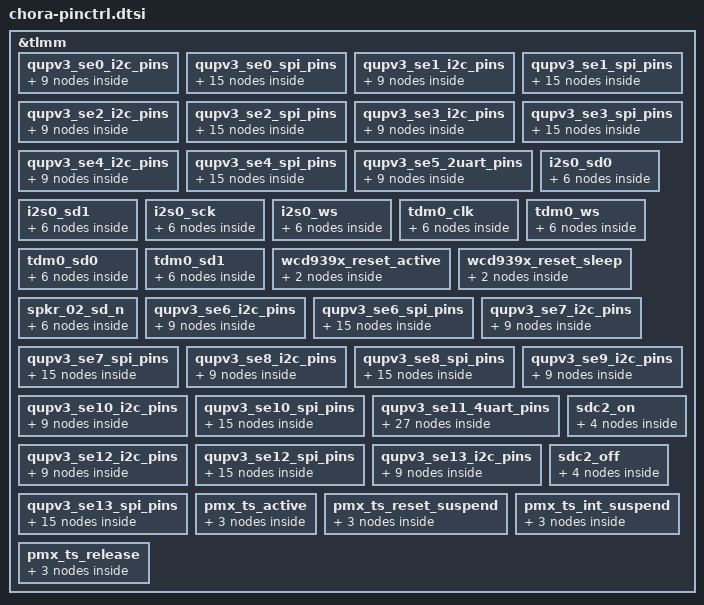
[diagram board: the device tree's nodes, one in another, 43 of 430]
// SPDX-License-Identifier: BSD-3-Clause
/*
 * Copyright (c) Qualcomm Technologies, Inc. and/or its subsidiaries.
 */

&tlmm {
	qupv3_se0_i2c_pins: qupv3_se0_i2c_pins {
		qupv3_se0_i2c_sda_active: qupv3_se0_i2c_sda_active {
			mux {
				pins = "gpio0";
				function = "qup0_se0_l0";
			};

			config {
				pins = "gpio0";
				drive-strength = <2>;
				bias-pull-up;
				qcom,i2c_pull;
			};
		};

		qupv3_se0_i2c_scl_active: qupv3_se0_i2c_scl_active {
			mux {
				pins = "gpio1";
				function = "qup0_se0_l1";
			};

			config {
				pins = "gpio1";
				drive-strength = <2>;
				bias-pull-up;
				qcom,i2c_pull;
			};
		};

		qupv3_se0_i2c_sleep: qupv3_se0_i2c_sleep {
			mux {
				pins = "gpio0", "gpio1";
				function = "gpio";
			};

			config {
				pins = "gpio0", "gpio1";
				drive-strength = <2>;
			};
		};
	};

	qupv3_se0_spi_pins: qupv3_se0_spi_pins {
		qupv3_se0_spi_miso_active: qupv3_se0_spi_miso_active {
			mux {
				pins = "gpio0";
				function = "qup0_se0_l0";
			};

			config {
				pins = "gpio0";
				drive-strength = <6>;
				bias-disable;
			};
		};

		qupv3_se0_spi_mosi_active: qupv3_se0_spi_mosi_active {
			mux {
				pins = "gpio1";
				function = "qup0_se0_l1";
			};

			config {
				pins = "gpio1";
				drive-strength = <6>;
				bias-disable;
			};
		};

		qupv3_se0_spi_clk_active: qupv3_se0_spi_clk_active {
			mux {
				pins = "gpio2";
				function = "qup0_se0_l2";
			};

			config {
				pins = "gpio2";
				drive-strength = <6>;
				bias-disable;
			};
		};

		qupv3_se0_spi_cs_active: qupv3_se0_spi_cs_active {
			mux {
				pins = "gpio3";
				function = "qup0_se0_l3";
			};

			config {
				pins = "gpio3";
				drive-strength = <6>;
				bias-disable;
			};
		};

		qupv3_se0_spi_sleep: qupv3_se0_spi_sleep {
			mux {
				pins = "gpio0", "gpio1",
					"gpio2", "gpio3";
				function = "gpio";
			};

			config {
				pins = "gpio0", "gpio1",
					"gpio2", "gpio3";
				drive-strength = <2>;
				bias-disable;
			};
		};
	};

	qupv3_se1_i2c_pins: qupv3_se1_i2c_pins {
		qupv3_se1_i2c_sda_active: qupv3_se1_i2c_sda_active {
			mux {
				pins = "gpio4";
				function = "qup0_se1_l0";
			};

			config {
				pins = "gpio4";
				drive-strength = <2>;
				bias-pull-up;
				qcom,i2c_pull;
			};
		};

		qupv3_se1_i2c_scl_active: qupv3_se1_i2c_scl_active {
			mux {
				pins = "gpio5";
				function = "qup0_se1_l1";
			};

			config {
				pins = "gpio5";
				drive-strength = <2>;
				bias-pull-up;
				qcom,i2c_pull;
			};
		};

		qupv3_se1_i2c_sleep: qupv3_se1_i2c_sleep {
			mux {
				pins = "gpio4", "gpio5";
				function = "gpio";
			};

			config {
				pins = "gpio4", "gpio5";
				drive-strength = <2>;
			};
		};
	};

	qupv3_se1_spi_pins: qupv3_se1_spi_pins {
		qupv3_se1_spi_miso_active: qupv3_se1_spi_miso_active {
			mux {
				pins = "gpio4";
				function = "qup0_se1_l0";
			};

			config {
				pins = "gpio4";
				drive-strength = <6>;
				bias-disable;
			};
		};

		qupv3_se1_spi_mosi_active: qupv3_se1_spi_mosi_active {
			mux {
				pins = "gpio5";
				function = "qup0_se1_l1";
			};

			config {
				pins = "gpio5";
				drive-strength = <6>;
				bias-disable;
			};
		};

		qupv3_se1_spi_clk_active: qupv3_se1_spi_clk_active {
			mux {
				pins = "gpio6";
				function = "qup0_se1_l2";
			};

			config {
				pins = "gpio6";
				drive-strength = <6>;
				bias-disable;
			};
		};

		qupv3_se1_spi_cs_active: qupv3_se1_spi_cs_active {
			mux {
				pins = "gpio7";
				function = "qup0_se1_l3";
			};

			config {
				pins = "gpio7";
				drive-strength = <6>;
				bias-disable;
			};
		};

		qupv3_se1_spi_sleep: qupv3_se1_spi_sleep {
			mux {
				pins = "gpio4", "gpio5",
					"gpio6", "gpio7";
				function = "gpio";
			};

			config {
				pins = "gpio4", "gpio5",
					"gpio6", "gpio7";
				drive-strength = <2>;
				bias-disable;
			};
		};
	};

	qupv3_se2_i2c_pins: qupv3_se2_i2c_pins {
		qupv3_se2_i2c_sda_active: qupv3_se2_i2c_sda_active {
			mux {
				pins = "gpio8";
				function = "qup0_se2_l0";
			};

			config {
				pins = "gpio8";
				drive-strength = <2>;
				bias-pull-up;
				qcom,i2c_pull;
			};
		};

		qupv3_se2_i2c_scl_active: qupv3_se2_i2c_scl_active {
			mux {
				pins = "gpio9";
				function = "qup0_se2_l1";
			};

			config {
				pins = "gpio9";
				drive-strength = <2>;
				bias-pull-up;
				qcom,i2c_pull;
			};
		};

		qupv3_se2_i2c_sleep: qupv3_se2_i2c_sleep {
			mux {
				pins = "gpio8", "gpio9";
				function = "gpio";
			};

			config {
				pins = "gpio8", "gpio9";
				drive-strength = <2>;
			};
		};
	};

	qupv3_se2_spi_pins: qupv3_se2_spi_pins {
		qupv3_se2_spi_miso_active: qupv3_se2_spi_miso_active {
			mux {
				pins = "gpio8";
				function = "qup0_se2_l0";
			};

			config {
				pins = "gpio8";
				drive-strength = <6>;
				bias-disable;
			};
		};

		qupv3_se2_spi_mosi_active: qupv3_se2_spi_mosi_active {
			mux {
				pins = "gpio9";
				function = "qup0_se2_l1";
			};

			config {
				pins = "gpio9";
				drive-strength = <6>;
				bias-disable;
			};
		};

		qupv3_se2_spi_clk_active: qupv3_se2_spi_clk_active {
			mux {
				pins = "gpio10";
				function = "qup0_se2_l2";
			};

			config {
				pins = "gpio10";
				drive-strength = <6>;
				bias-disable;
			};
		};

		qupv3_se2_spi_cs_active: qupv3_se2_spi_cs_active {
			mux {
				pins = "gpio11";
				function = "qup0_se2_l3";
			};

			config {
				pins = "gpio11";
				drive-strength = <6>;
				bias-disable;
			};
		};

		qupv3_se2_spi_sleep: qupv3_se2_spi_sleep {
			mux {
				pins = "gpio8", "gpio9",
					"gpio10", "gpio11";
				function = "gpio";
			};

			config {
				pins = "gpio8", "gpio9",
					"gpio10", "gpio11";
				drive-strength = <2>;
				bias-disable;
			};
		};
	};

	qupv3_se3_i2c_pins: qupv3_se3_i2c_pins {
		qupv3_se3_i2c_sda_active: qupv3_se3_i2c_sda_active {
			mux {
				pins = "gpio15";
				function = "qup0_se3_l0";
			};

			config {
				pins = "gpio15";
				drive-strength = <2>;
				bias-pull-up;
				qcom,i2c_pull;
			};
		};

		qupv3_se3_i2c_scl_active: qupv3_se3_i2c_scl_active {
			mux {
				pins = "gpio16";
				function = "qup0_se3_l1";
			};

			config {
				pins = "gpio16";
				drive-strength = <2>;
				bias-pull-up;
				qcom,i2c_pull;
			};
		};

		qupv3_se3_i2c_sleep: qupv3_se3_i2c_sleep {
			mux {
				pins = "gpio15", "gpio16";
				function = "gpio";
			};

			config {
				pins = "gpio15", "gpio16";
				drive-strength = <2>;
			};
		};
	};

	qupv3_se3_spi_pins: qupv3_se3_spi_pins {
		qupv3_se3_spi_miso_active: qupv3_se3_spi_miso_active {
			mux {
				pins = "gpio15";
				function = "qup0_se3_l0";
			};

			config {
				pins = "gpio15";
				drive-strength = <6>;
				bias-disable;
			};
		};

		qupv3_se3_spi_mosi_active: qupv3_se3_spi_mosi_active {
			mux {
				pins = "gpio16";
				function = "qup0_se3_l1";
			};

			config {
				pins = "gpio16";
				drive-strength = <6>;
				bias-disable;
			};
		};

		qupv3_se3_spi_clk_active: qupv3_se3_spi_clk_active {
			mux {
				pins = "gpio17";
				function = "qup0_se3_l2";
			};

			config {
				pins = "gpio17";
				drive-strength = <6>;
				bias-disable;
			};
		};

		qupv3_se3_spi_cs_active: qupv3_se3_spi_cs_active {
			mux {
				pins = "gpio18";
				function = "qup0_se3_l3";
			};

			config {
				pins = "gpio18";
				drive-strength = <6>;
				bias-disable;
			};
		};

		qupv3_se3_spi_sleep: qupv3_se3_spi_sleep {
			mux {
				pins = "gpio15", "gpio16",
					"gpio17", "gpio18";
				function = "gpio";
			};

			config {
				pins = "gpio15", "gpio16",
					"gpio17", "gpio18";
				drive-strength = <2>;
				bias-disable;
			};
		};
	};

	qupv3_se4_i2c_pins: qupv3_se4_i2c_pins {
		qupv3_se4_i2c_sda_active: qupv3_se4_i2c_sda_active {
			mux {
				pins = "gpio19";
				function = "qup0_se4_l0";
			};

			config {
				pins = "gpio19";
				drive-strength = <2>;
				bias-pull-up;
				qcom,i2c_pull;
			};
		};

		qupv3_se4_i2c_scl_active: qupv3_se4_i2c_scl_active {
			mux {
				pins = "gpio20";
				function = "qup0_se4_l1";
			};

			config {
				pins = "gpio20";
				drive-strength = <2>;
				bias-pull-up;
				qcom,i2c_pull;
			};
		};

		qupv3_se4_i2c_sleep: qupv3_se4_i2c_sleep {
			mux {
				pins = "gpio19", "gpio20";
				function = "gpio";
			};

			config {
				pins = "gpio19", "gpio20";
				drive-strength = <2>;
			};
		};
	};

	qupv3_se4_spi_pins: qupv3_se4_spi_pins {
		qupv3_se4_spi_miso_active: qupv3_se4_spi_miso_active {
			mux {
				pins = "gpio19";
				function = "qup0_se4_l0";
			};

			config {
				pins = "gpio19";
				drive-strength = <6>;
				bias-disable;
			};
		};

		qupv3_se4_spi_mosi_active: qupv3_se4_spi_mosi_active {
			mux {
				pins = "gpio20";
				function = "qup0_se4_l1";
			};

			config {
				pins = "gpio20";
				drive-strength = <6>;
				bias-disable;
			};
		};

		qupv3_se4_spi_clk_active: qupv3_se4_spi_clk_active {
			mux {
				pins = "gpio21";
				function = "qup0_se4_l2";
			};

			config {
				pins = "gpio21";
				drive-strength = <6>;
				bias-disable;
			};
		};

		qupv3_se4_spi_cs_active: qupv3_se4_spi_cs_active {
			mux {
				pins = "gpio22";
				function = "qup0_se4_l3";
			};

			config {
				pins = "gpio22";
				drive-strength = <6>;
				bias-disable;
			};
		};

		qupv3_se4_spi_sleep: qupv3_se4_spi_sleep {
			mux {
				pins = "gpio19", "gpio20",
					"gpio21", "gpio22";
				function = "gpio";
			};

			config {
				pins = "gpio19", "gpio20",
					"gpio21", "gpio22";
				drive-strength = <2>;
				bias-disable;
			};
		};
	};

	qupv3_se5_2uart_pins: qupv3_se5_2uart_pins {
		qupv3_se5_2uart_tx_active: qupv3_se5_2uart_tx_active {
			mux {
				pins = "gpio25";
				function = "qup0_se5_l2";
			};

			config {
				pins = "gpio25";
				drive-strength = <2>;
				bias-disable;
			};
		};

		qupv3_se5_2uart_rx_active: qupv3_se5_2uart_rx_active {
			mux {
				pins = "gpio26";
				function = "qup0_se5_l3";
			};

			config {
				pins = "gpio26";
				drive-strength = <2>;
				bias-disable;
			};
		};

		qupv3_se5_2uart_sleep: qupv3_se5_2uart_sleep {
			mux {
				pins = "gpio25", "gpio26";
				function = "gpio";
			};

			config {
				pins = "gpio25", "gpio26";
				drive-strength = <2>;
				bias-pull-down;
			};
		};
	};


	i2s0_sd0 {
		i2s0_sd0_sleep: i2s0_sd0_sleep {
			mux {
				pins = "gpio16";
				function = "gpio";
			};

			config {
				pins = "gpio16";
				drive-strength = <2>;   /* 2 mA */
				bias-pull-down;         /* PULL DOWN */
				input-enable;
			};
		};

		i2s0_sd0_active: i2s0_sd0_active {
			mux {
				pins = "gpio16";
				function = "i2s0_data0";
			};

			config {
				pins = "gpio16";
				drive-strength = <8>;   /* 8 mA */
				bias-disable;           /* NO PULL */
				output-high;
			};
		};
	};

	i2s0_sd1 {
		i2s0_sd1_sleep: i2s0_sd1_sleep {
			mux {
				pins = "gpio15";
				function = "gpio";
			};

			config {
				pins = "gpio15";
				drive-strength = <2>;   /* 2 mA */
				bias-pull-down;         /* PULL DOWN */
				input-enable;
			};
		};

		i2s0_sd1_active: i2s0_sd1_active {
			mux {
				pins = "gpio15";
				function = "i2s0_data1";
			};

			config {
				pins = "gpio15";
				drive-strength = <8>;   /* 8 mA */
				bias-disable;           /* NO PULL */
				output-high;
			};
		};
	};

	i2s0_sck {
		i2s0_sck_sleep: i2s0_sck_sleep {
			mux {
				pins = "gpio17";
				function = "gpio";
			};

			config {
				pins = "gpio17";
				drive-strength = <2>;   /* 2 mA */
				bias-pull-down;         /* PULL DOWN */
				input-enable;
			};
		};

		i2s0_sck_active: i2s0_sck_active {
			mux {
				pins = "gpio17";
				function = "i2s0_sck";
			};

			config {
				pins = "gpio17";
				drive-strength = <8>;   /* 8 mA */
				bias-disable;           /* NO PULL */
			};
		};
	};

	i2s0_ws {
		i2s0_ws_sleep: i2s0_ws_sleep {
			mux {
				pins = "gpio18";
				function = "gpio";
			};

			config {
				pins = "gpio18";
				drive-strength = <2>;   /* 2 mA */
				bias-pull-down;         /* PULL DOWN */
				input-enable;
			};
		};

		i2s0_ws_active: i2s0_ws_active {
			mux {
				pins = "gpio18";
				function = "i2s0_ws";
			};

			config {
				pins = "gpio18";
				drive-strength = <8>;   /* 8 mA */
				bias-disable;           /* NO PULL */
			};
		};
	};

	tdm0_clk {
		tdm0_clk_sleep: tdm0_clk_sleep {
			mux {
				pins = "gpio17";
				function = "gpio";
			};

			config {
				pins = "gpio17";
				drive-strength = <2>;   /* 2 mA */
				bias-pull-down;         /* PULL DOWN */
				input-enable;
			};
		};

		tdm0_clk_active: tdm0_clk_active {
			mux {
				pins = "gpio17";
				function = "i2s0_sck";
			};

			config {
				pins = "gpio17";
				drive-strength = <8>;   /* 8 mA */
				bias-disable;           /* NO PULL */
				output-high;
			};
		};
	};

	tdm0_ws {
		tdm0_ws_sleep: tdm0_ws_sleep {
			mux {
				pins = "gpio18";
				function = "gpio";
			};

			config {
				pins = "gpio18";
				drive-strength = <2>;   /* 2 mA */
				bias-pull-down;         /* PULL DOWN */
				input-enable;
			};
		};

		tdm0_ws_active: tdm0_ws_active {
			mux {
				pins = "gpio18";
				function = "i2s0_ws";
			};

			config {
				pins = "gpio18";
				drive-strength = <8>;   /* 8 mA */
				bias-disable;           /* NO PULL */
				output-high;
			};
		};
	};

	tdm0_sd0 {
		tdm0_sd0_sleep: tdm0_sd0_sleep {
			mux {
				pins = "gpio16";
				function = "gpio";
			};

			config {
				pins = "gpio16";
				drive-strength = <2>;   /* 2 mA */
				bias-pull-down;         /* PULL DOWN */
				input-enable;
			};
		};

		tdm0_sd0_active: tdm0_sd0_active {
			mux {
				pins = "gpio16";
				function = "i2s0_data0";
			};

			config {
				pins = "gpio16";
				drive-strength = <8>;   /* 8 mA */
				bias-disable;           /* NO PULL */
			};
		};
	};

	tdm0_sd1 {
		tdm0_sd1_sleep: tdm0_sd1_sleep {
			mux {
				pins = "gpio15";
				function = "gpio";
			};

			config {
				pins = "gpio15";
				drive-strength = <2>;   /* 2 mA */
				bias-pull-down;         /* PULL DOWN */
				input-enable;
			};
		};

		tdm0_sd1_active: tdm0_sd1_active {
			mux {
				pins = "gpio15";
				function = "i2s0_data1";
			};

			config {
				pins = "gpio15";
				drive-strength = <8>;   /* 8 mA */
				bias-disable;           /* NO PULL */
			};
		};
	};

	/* WCD reset pin */
	wcd939x_reset_active: wcd939x_reset_active {
		mux {
			pins = "gpio106";
			function = "gpio";
		};

		config {
			pins = "gpio106";
			drive-strength = <16>;
			output-high;
		};
	};

	wcd939x_reset_sleep: wcd939x_reset_sleep {
		mux {
			pins = "gpio106";
			function = "gpio";
		};

		config {
			pins = "gpio106";
			drive-strength = <16>;
			bias-disable;
			output-low;
		};
	};

	/* Pandeiro speaker - north reset pins */
	spkr_02_sd_n {
		spkr_02_sd_n_sleep: spkr_02_sd_n_sleep {
			mux {
				pins = "gpio133";
				function = "gpio";
			};

			config {
				pins = "gpio133";
				drive-strength = <2>;   /* 2 mA */
				bias-pull-down;
				input-enable;
			};
		};

		spkr_02_sd_n_active: spkr_02_sd_n_active {
			mux {
				pins = "gpio133";
				function = "gpio";
			};

			config {
				pins = "gpio133";
				drive-strength = <16>;   /* 16 mA */
				bias-disable;
				output-high;
			};
		};
	};

	qupv3_se6_i2c_pins: qupv3_se6_i2c_pins {
		qupv3_se6_i2c_sda_active: qupv3_se6_i2c_sda_active {
			mux {
				pins = "gpio27";
				function = "qup0_se6_l0";
			};

			config {
				pins = "gpio27";
				drive-strength = <2>;
				bias-pull-up;
				qcom,i2c_pull;
			};
		};

		qupv3_se6_i2c_scl_active: qupv3_se6_i2c_scl_active {
			mux {
				pins = "gpio28";
				function = "qup0_se6_l1";
			};

			config {
				pins = "gpio28";
				drive-strength = <2>;
				bias-pull-up;
				qcom,i2c_pull;
			};
		};

		qupv3_se6_i2c_sleep: qupv3_se6_i2c_sleep {
			mux {
				pins = "gpio27", "gpio28";
				function = "gpio";
			};

			config {
				pins = "gpio27", "gpio28";
				drive-strength = <2>;
			};
		};
	};

	qupv3_se6_spi_pins: qupv3_se6_spi_pins {
		qupv3_se6_spi_miso_active: qupv3_se6_spi_miso_active {
			mux {
				pins = "gpio27";
				function = "qup0_se6_l0";
			};

			config {
				pins = "gpio27";
				drive-strength = <6>;
				bias-disable;
			};
		};

		qupv3_se6_spi_mosi_active: qupv3_se6_spi_mosi_active {
			mux {
				pins = "gpio28";
				function = "qup0_se6_l1";
			};

			config {
				pins = "gpio28";
				drive-strength = <6>;
				bias-disable;
			};
		};

		qupv3_se6_spi_clk_active: qupv3_se6_spi_clk_active {
			mux {
				pins = "gpio29";
				function = "qup0_se6_l2";
			};

			config {
				pins = "gpio29";
				drive-strength = <6>;
				bias-disable;
			};
		};

		qupv3_se6_spi_cs_active: qupv3_se6_spi_cs_active {
			mux {
				pins = "gpio30";
				function = "qup0_se6_l3";
			};

			config {
				pins = "gpio30";
				drive-strength = <6>;
				bias-disable;
			};
		};

		qupv3_se6_spi_sleep: qupv3_se6_spi_sleep {
			mux {
				pins = "gpio27", "gpio28",
					"gpio29", "gpio30";
				function = "gpio";
			};

			config {
				pins = "gpio27", "gpio28",
					"gpio29", "gpio30";
				drive-strength = <2>;
				bias-disable;
			};
		};
	};

	qupv3_se7_i2c_pins: qupv3_se7_i2c_pins {
		qupv3_se7_i2c_sda_active: qupv3_se7_i2c_sda_active {
			mux {
				pins = "gpio32";
				function = "qup1_se0_l0";
			};

			config {
				pins = "gpio32";
				drive-strength = <2>;
				bias-pull-up;
				qcom,i2c_pull;
			};
		};

		qupv3_se7_i2c_scl_active: qupv3_se7_i2c_scl_active {
			mux {
				pins = "gpio33";
				function = "qup1_se0_l1";
			};

			config {
				pins = "gpio33";
				drive-strength = <2>;
				bias-pull-up;
				qcom,i2c_pull;
			};
		};

		qupv3_se7_i2c_sleep: qupv3_se7_i2c_sleep {
			mux {
				pins = "gpio32", "gpio33";
				function = "gpio";
			};

			config {
				pins = "gpio32", "gpio33";
				drive-strength = <2>;
			};
		};
	};

	qupv3_se7_spi_pins: qupv3_se7_spi_pins {
		qupv3_se7_spi_miso_active: qupv3_se7_spi_miso_active {
			mux {
				pins = "gpio32";
				function = "qup1_se0_l0";
			};

			config {
				pins = "gpio32";
				drive-strength = <6>;
				bias-disable;
			};
		};

		qupv3_se7_spi_mosi_active: qupv3_se7_spi_mosi_active {
			mux {
				pins = "gpio33";
				function = "qup1_se0_l1";
			};

			config {
				pins = "gpio33";
				drive-strength = <6>;
				bias-disable;
			};
		};

		qupv3_se7_spi_clk_active: qupv3_se7_spi_clk_active {
			mux {
				pins = "gpio46";
				function = "qup1_se0_l2";
			};

			config {
				pins = "gpio46";
				drive-strength = <6>;
				bias-disable;
			};
		};

		qupv3_se7_spi_cs_active: qupv3_se7_spi_cs_active {
			mux {
				pins = "gpio47";
				function = "qup1_se0_l3";
			};

			config {
				pins = "gpio47";
				drive-strength = <6>;
				bias-disable;
			};
		};

		qupv3_se7_spi_sleep: qupv3_se7_spi_sleep {
			mux {
				pins = "gpio32", "gpio33",
					"gpio46", "gpio47";
				function = "gpio";
			};

			config {
				pins = "gpio32", "gpio33",
					"gpio46", "gpio47";
				drive-strength = <2>;
				bias-disable;
			};
		};
	};

	qupv3_se8_i2c_pins: qupv3_se8_i2c_pins {
		qupv3_se8_i2c_sda_active: qupv3_se8_i2c_sda_active {
			mux {
				pins = "gpio36";
				function = "qup1_se1_l0";
			};

			config {
				pins = "gpio36";
				drive-strength = <2>;
				bias-pull-up;
				qcom,i2c_pull;
			};
		};

		qupv3_se8_i2c_scl_active: qupv3_se8_i2c_scl_active {
			mux {
				pins = "gpio39";
				function = "qup1_se1_l1_mirb";
			};

			config {
				pins = "gpio39";
				drive-strength = <2>;
				bias-pull-up;
				qcom,i2c_pull;
			};
		};

		qupv3_se8_i2c_sleep: qupv3_se8_i2c_sleep {
			mux {
				pins = "gpio36", "gpio39";
				function = "gpio";
			};

			config {
				pins = "gpio36", "gpio39";
				drive-strength = <2>;
			};
		};
	};

	qupv3_se8_spi_pins: qupv3_se8_spi_pins {
		qupv3_se8_spi_miso_active: qupv3_se8_spi_miso_active {
			mux {
				pins = "gpio36";
				function = "qup1_se1_l0";
			};

			config {
				pins = "gpio36";
				drive-strength = <6>;
				bias-disable;
			};
		};

		qupv3_se8_spi_mosi_active: qupv3_se8_spi_mosi_active {
			mux {
				pins = "gpio39";
				function = "qup1_se1_l1_mirb";
			};

			config {
				pins = "gpio39";
				drive-strength = <6>;
				bias-disable;
			};
		};

		qupv3_se8_spi_clk_active: qupv3_se8_spi_clk_active {
			mux {
				pins = "gpio37";
				function = "qup1_se1_l2";
			};

			config {
				pins = "gpio37";
				drive-strength = <6>;
				bias-disable;
			};
		};

		qupv3_se8_spi_cs_active: qupv3_se8_spi_cs_active {
			mux {
				pins = "gpio38";
				function = "qup1_se1_l3_mirb";
			};

			config {
				pins = "gpio38";
				drive-strength = <6>;
				bias-disable;
			};
		};

		qupv3_se8_spi_sleep: qupv3_se8_spi_sleep {
			mux {
				pins = "gpio36", "gpio39",
					"gpio37", "gpio38";
				function = "gpio";
			};

			config {
				pins = "gpio36", "gpio39",
					"gpio37", "gpio38";
				drive-strength = <2>;
				bias-disable;
			};
		};
	};

	qupv3_se9_i2c_pins: qupv3_se9_i2c_pins {
		qupv3_se9_i2c_sda_active: qupv3_se9_i2c_sda_active {
			mux {
				pins = "gpio38";
				function = "qup1_se2_l0";
			};

			config {
				pins = "gpio38";
				drive-strength = <2>;
				bias-pull-up;
				qcom,i2c_pull;
			};
		};

		qupv3_se9_i2c_scl_active: qupv3_se9_i2c_scl_active {
			mux {
				pins = "gpio39";
				function = "qup1_se2_l1";
			};

			config {
				pins = "gpio39";
				drive-strength = <2>;
				bias-pull-up;
				qcom,i2c_pull;
			};
		};

		qupv3_se9_i2c_sleep: qupv3_se9_i2c_sleep {
			mux {
				pins = "gpio38", "gpio39";
				function = "gpio";
			};

			config {
				pins = "gpio38", "gpio39";
				drive-strength = <2>;
			};
		};
	};

	qupv3_se10_i2c_pins: qupv3_se10_i2c_pins {
		qupv3_se10_i2c_sda_active: qupv3_se10_i2c_sda_active {
			mux {
				pins = "gpio81";
				function = "qup1_se3_l0";
			};

			config {
				pins = "gpio81";
				drive-strength = <2>;
				bias-pull-up;
				qcom,i2c_pull;
			};
		};

		qupv3_se10_i2c_scl_active: qupv3_se10_i2c_scl_active {
			mux {
				pins = "gpio82";
				function = "qup1_se3_l1";
			};

			config {
				pins = "gpio82";
				drive-strength = <2>;
				bias-pull-up;
				qcom,i2c_pull;
			};
		};

		qupv3_se10_i2c_sleep: qupv3_se10_i2c_sleep {
			mux {
				pins = "gpio81", "gpio82";
				function = "gpio";
			};

			config {
				pins = "gpio81", "gpio82";
				drive-strength = <2>;
			};
		};
	};

	qupv3_se10_spi_pins: qupv3_se10_spi_pins {
		qupv3_se10_spi_miso_active: qupv3_se10_spi_miso_active {
			mux {
				pins = "gpio81";
				function = "qup1_se3_l0";
			};

			config {
				pins = "gpio81";
				drive-strength = <6>;
				bias-disable;
			};
		};

		qupv3_se10_spi_mosi_active: qupv3_se10_spi_mosi_active {
			mux {
				pins = "gpio82";
				function = "qup1_se3_l1";
			};

			config {
				pins = "gpio82";
				drive-strength = <6>;
				bias-disable;
			};
		};

		qupv3_se10_spi_clk_active: qupv3_se10_spi_clk_active {
			mux {
				pins = "gpio83";
				function = "qup1_se3_l2";
			};

			config {
				pins = "gpio83";
				drive-strength = <6>;
				bias-disable;
			};
		};

		qupv3_se10_spi_cs_active: qupv3_se10_spi_cs_active {
			mux {
				pins = "gpio84";
				function = "qup1_se3_l3";
			};

			config {
				pins = "gpio84";
				drive-strength = <6>;
				bias-disable;
			};
		};

		qupv3_se10_spi_sleep: qupv3_se10_spi_sleep {
			mux {
				pins = "gpio81", "gpio82",
					"gpio83", "gpio84";
				function = "gpio";
			};

			config {
				pins = "gpio81", "gpio82",
					"gpio83", "gpio84";
				drive-strength = <2>;
				bias-disable;
			};
		};
	};

	qupv3_se11_4uart_pins: qupv3_se11_4uart_pins {
		qupv3_se11_default_cts: qupv3_se11_default_cts {
			mux {
				pins = "gpio44";
				function = "gpio";
			};

			config {
				pins = "gpio44";
				drive-strength = <2>;
				bias-disable;
			};
		};

		qupv3_se11_default_rts: qupv3_se11_default_rts {
			mux {
				pins = "gpio45";
				function = "gpio";
			};

			config {
				pins = "gpio45";
				drive-strength = <2>;
				bias-pull-down;
			};
		};

		qupv3_se11_default_tx: qupv3_se11_default_tx {
			mux {
				pins = "gpio46";
				function = "gpio";
			};

			config {
				pins = "gpio46";
				drive-strength = <2>;
				bias-pull-up;
			};
		};

		qupv3_se11_default_rx: qupv3_se11_default_rx {
			mux {
				pins = "gpio47";
				function = "gpio";
			};

			config {
				pins = "gpio47";
				drive-strength = <2>;
				bias-pull-down;
			};
		};

		qupv3_se11_cts: qupv3_se11_cts {
			mux {
				pins = "gpio44";
				function = "qup1_se4_l0";
			};

			config {
				pins = "gpio44";
				drive-strength = <2>;
				bias-disable;
			};
		};

		qupv3_se11_rts: qupv3_se11_rts {
			mux {
				pins = "gpio45";
				function = "qup1_se4_l1";
			};

			config {
				pins = "gpio45";
				drive-strength = <2>;
				bias-pull-down;
			};
		};

		qupv3_se11_tx: qupv3_se11_tx {
			mux {
				pins = "gpio46";
				function = "qup1_se4_l2";
			};

			config {
				pins = "gpio46";
				drive-strength = <2>;
				bias-pull-up;
			};
		};

		qupv3_se11_rx_active: qupv3_se11_rx_active {
			mux {
				pins = "gpio47";
				function = "qup1_se4_l3";
			};

			config {
				pins = "gpio47";
				drive-strength = <2>;
				bias-disable;
			};
		};

		/* RX to be in gpio mode for sleep config */
		qupv3_se11_rx_wake: qupv3_se11_rx_wake {
			mux {
				pins = "gpio47";
				function = "gpio";
			};

			config {
				pins = "gpio47";
				drive-strength = <2>;
				bias-disable;
			};
		};
	};

	qupv3_se12_i2c_pins: qupv3_se12_i2c_pins {
		qupv3_se12_i2c_sda_active: qupv3_se12_i2c_sda_active {
			mux {
				pins = "gpio49";
				function = "qup1_se5_l0";
			};

			config {
				pins = "gpio49";
				drive-strength = <2>;
				bias-pull-up;
				qcom,i2c_pull;
			};
		};

		qupv3_se12_i2c_scl_active: qupv3_se12_i2c_scl_active {
			mux {
				pins = "gpio50";
				function = "qup1_se5_l1";
			};

			config {
				pins = "gpio50";
				drive-strength = <2>;
				bias-pull-up;
				qcom,i2c_pull;
			};
		};

		qupv3_se12_i2c_sleep: qupv3_se12_i2c_sleep {
			mux {
				pins = "gpio49", "gpio50";
				function = "gpio";
			};

			config {
				pins = "gpio49", "gpio50";
				drive-strength = <2>;
			};
		};
	};

	qupv3_se12_spi_pins: qupv3_se12_spi_pins {
		qupv3_se12_spi_miso_active: qupv3_se12_spi_miso_active {
			mux {
				pins = "gpio49";
				function = "qup1_se5_l0";
			};

			config {
				pins = "gpio49";
				drive-strength = <6>;
				bias-disable;
			};
		};

		qupv3_se12_spi_mosi_active: qupv3_se12_spi_mosi_active {
			mux {
				pins = "gpio50";
				function = "qup1_se5_l1";
			};

			config {
				pins = "gpio50";
				drive-strength = <6>;
				bias-disable;
			};
		};

		qupv3_se12_spi_clk_active: qupv3_se12_spi_clk_active {
			mux {
				pins = "gpio53";
				function = "qup1_se5_l2";
			};

			config {
				pins = "gpio53";
				drive-strength = <6>;
				bias-disable;
			};
		};

		qupv3_se12_spi_cs_active: qupv3_se12_spi_cs_active {
			mux {
				pins = "gpio54";
				function = "qup1_se5_l3";
			};

			config {
				pins = "gpio54";
				drive-strength = <6>;
				bias-disable;
			};
		};

		qupv3_se12_spi_sleep: qupv3_se12_spi_sleep {
			mux {
				pins = "gpio49", "gpio50",
					"gpio53", "gpio54";
				function = "gpio";
			};

			config {
				pins = "gpio49", "gpio50",
					"gpio53", "gpio54";
				drive-strength = <2>;
				bias-disable;
			};
		};
	};

	qupv3_se13_i2c_pins: qupv3_se13_i2c_pins {
		qupv3_se13_i2c_sda_active: qupv3_se13_i2c_sda_active {
			mux {
				pins = "gpio53";
				function = "qup1_se6_l0";
			};

			config {
				pins = "gpio53";
				drive-strength = <2>;
				bias-pull-up;
				qcom,i2c_pull;
			};
		};

		qupv3_se13_i2c_scl_active: qupv3_se13_i2c_scl_active {
			mux {
				pins = "gpio54";
				function = "qup1_se6_l1";
			};

			config {
				pins = "gpio54";
				drive-strength = <2>;
				bias-pull-up;
				qcom,i2c_pull;
			};
		};

		qupv3_se13_i2c_sleep: qupv3_se13_i2c_sleep {
			mux {
				pins = "gpio53", "gpio54";
				function = "gpio";
			};

			config {
				pins = "gpio53", "gpio54";
				drive-strength = <2>;
			};
		};
	};

	qupv3_se13_spi_pins: qupv3_se13_spi_pins {
		qupv3_se13_spi_miso_active: qupv3_se13_spi_miso_active {
			mux {
				pins = "gpio53";
				function = "qup1_se6_l0";
			};

			config {
				pins = "gpio53";
				drive-strength = <6>;
				bias-disable;
			};
		};

		qupv3_se13_spi_mosi_active: qupv3_se13_spi_mosi_active {
			mux {
				pins = "gpio54";
				function = "qup1_se6_l1";
			};

			config {
				pins = "gpio54";
				drive-strength = <6>;
				bias-disable;
			};
		};

		qupv3_se13_spi_clk_active: qupv3_se13_spi_clk_active {
			mux {
				pins = "gpio79";
				function = "qup1_se6_l2_mirb";
			};

			config {
				pins = "gpio79";
				drive-strength = <6>;
				bias-disable;
			};
		};

		qupv3_se13_spi_cs_active: qupv3_se13_spi_cs_active {
			mux {
				pins = "gpio80";
				function = "qup1_se6_l3_mirb";
			};

			config {
				pins = "gpio80";
				drive-strength = <6>;
				bias-disable;
			};
		};

		qupv3_se13_spi_sleep: qupv3_se13_spi_sleep {
			mux {
				pins = "gpio53", "gpio54",
					"gpio79", "gpio80";
				function = "gpio";
			};

			config {
				pins = "gpio53", "gpio54",
					"gpio79", "gpio80";
				drive-strength = <2>;
				bias-disable;
			};
		};
	};

	sdc2_on: sdc2_on {
		clk {
			pins = "gpio56";
			function = "sdc2_clk";
			bias-disable;
			drive-strength = <16>;
		};

		cmd {
			pins = "gpio55";
			function = "sdc2_cmd";
			bias-pull-up;
			drive-strength = <10>;
		};

		data {
			pins = "gpio52", "gpio51", "gpio35", "gpio34";
			function = "sdc2_data";
			bias-pull-up;
			drive-strength = <10>;
		};

		sd-cd {
			pins = "gpio59";
			bias-pull-up;
			drive-strength = <2>;
		};
	};

	sdc2_off: sdc2_off {
		clk {
			pins = "gpio56";
			function = "gpio";
			bias-disable;
			drive-strength = <2>;
		};

		cmd {
			pins = "gpio55";
			function = "gpio";
			bias-pull-up;
			drive-strength = <2>;
		};

		data {
			pins = "gpio52", "gpio51", "gpio35", "gpio34";
			function = "gpio";
			bias-pull-up;
			drive-strength = <2>;
		};

		sd-cd {
			pins = "gpio59";
			bias-pull-up;
			drive-strength = <2>;
		};
	};

	/* touchscreen pins */
	pmx_ts_active {
		ts_active: ts_active {
			mux {
				pins = "gpio0", "gpio1";
				function = "gpio";
			};

			config {
				pins = "gpio0", "gpio1";
				drive-strength = <8>;
				bias-pull-up;
			};
		};
	};

	pmx_ts_reset_suspend {
		ts_reset_suspend: ts_reset_suspend {
			mux {
				pins = "gpio0";
				function = "gpio";
			};

			config {
				pins = "gpio0";
				drive-strength = <2>;
				bias-pull-down;
			};
		};
	};

	pmx_ts_int_suspend {
		ts_int_suspend: ts_int_suspend {
			mux {
				pins = "gpio1";
				function = "gpio";
			};

			config {
				pins = "gpio1";
				drive-strength = <2>;
				bias-pull-down;
			};
		};
	};

	pmx_ts_release {
		ts_release: ts_release {
			mux {
				pins = "gpio0", "gpio1";
				function = "gpio";
			};

			config {
				pins = "gpio0", "gpio1";
				drive-strength = <2>;
				bias-disable;
			};
		};
	};
};
